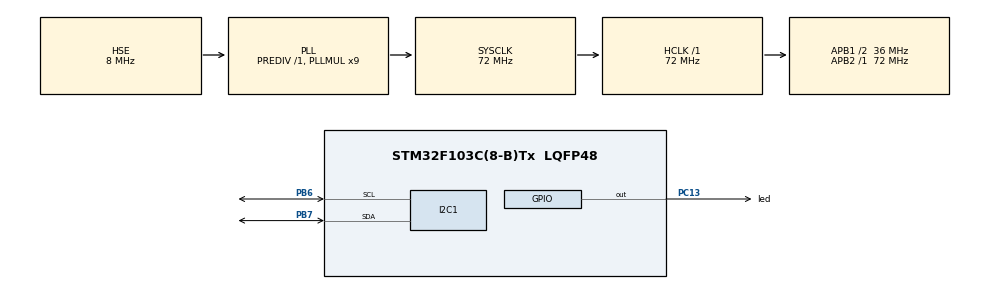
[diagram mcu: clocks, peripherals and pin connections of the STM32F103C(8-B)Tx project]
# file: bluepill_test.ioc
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I2C1.I2C_Mode=I2C_Fast
Mcu.Family=STM32F1
Mcu.Name=STM32F103C(8-B)Tx
Mcu.Package=LQFP48
NVIC.PriorityGroup=NVIC_PRIORITYGROUP_4
PA13.Mode=Serial_Wire
PA13.Signal=SYS_JTMS-SWDIO
PA14.Mode=Serial_Wire
PA14.Signal=SYS_JTCK-SWCLK
PB6.Mode=I2C
PB6.Signal=I2C1_SCL
PB7.Mode=I2C
PB7.Signal=I2C1_SDA
PC13-TAMPER-RTC.GPIO_Label=led
PC13-TAMPER-RTC.PinState=GPIO_PIN_SET
PC13-TAMPER-RTC.Signal=GPIO_Output
PD0-OSC_IN.Mode=HSE-External-Oscillator
PD0-OSC_IN.Signal=RCC_OSC_IN
PD1-OSC_OUT.Mode=HSE-External-Oscillator
PD1-OSC_OUT.Signal=RCC_OSC_OUT
ProjectManager.HeapSize=0x200
ProjectManager.StackSize=0x400
ProjectManager.TargetToolchain=SW4STM32
RCC.AHBFreq_Value=72000000
RCC.APB1CLKDivider=RCC_HCLK_DIV2
RCC.APB1Freq_Value=36000000
RCC.APB1TimFreq_Value=72000000
RCC.APB2Freq_Value=72000000
RCC.APB2TimFreq_Value=72000000
RCC.HCLKFreq_Value=72000000
RCC.PLLMUL=RCC_PLL_MUL9
RCC.PLLSourceVirtual=RCC_PLLSOURCE_HSE
RCC.SYSCLKFreq_VALUE=72000000
RCC.SYSCLKSource=RCC_SYSCLKSOURCE_PLLCLK
RCC.USBFreq_Value=72000000
board=bluepill_test

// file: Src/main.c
/**
 ******************************************************************************
 * File Name          : main.c
 * Description        : Main program body
 ******************************************************************************
 *
 * COPYRIGHT(c) 2017 STMicroelectronics
 *
 * Redistribution and use in source and binary forms, with or without modification,
 * are permitted provided that the following conditions are met:
 *   1. Redistributions of source code must retain the above copyright notice,
 *      this list of conditions and the following disclaimer.
 *   2. Redistributions in binary form must reproduce the above copyright notice,
 *      this list of conditions and the following disclaimer in the documentation
 *      and/or other materials provided with the distribution.
 *   3. Neither the name of STMicroelectronics nor the names of its contributors
 *      may be used to endorse or promote products derived from this software
 *      without specific prior written permission.
 *
 * THIS SOFTWARE IS PROVIDED BY THE COPYRIGHT HOLDERS AND CONTRIBUTORS "AS IS"
 * AND ANY EXPRESS OR IMPLIED WARRANTIES, INCLUDING, BUT NOT LIMITED TO, THE
 * IMPLIED WARRANTIES OF MERCHANTABILITY AND FITNESS FOR A PARTICULAR PURPOSE ARE
 * DISCLAIMED. IN NO EVENT SHALL THE COPYRIGHT HOLDER OR CONTRIBUTORS BE LIABLE
 * FOR ANY DIRECT, INDIRECT, INCIDENTAL, SPECIAL, EXEMPLARY, OR CONSEQUENTIAL
 * DAMAGES (INCLUDING, BUT NOT LIMITED TO, PROCUREMENT OF SUBSTITUTE GOODS OR
 * SERVICES; LOSS OF USE, DATA, OR PROFITS; OR BUSINESS INTERRUPTION) HOWEVER
 * CAUSED AND ON ANY THEORY OF LIABILITY, WHETHER IN CONTRACT, STRICT LIABILITY,
 * OR TORT (INCLUDING NEGLIGENCE OR OTHERWISE) ARISING IN ANY WAY OUT OF THE USE
 * OF THIS SOFTWARE, EVEN IF ADVISED OF THE POSSIBILITY OF SUCH DAMAGE.
 *
 ******************************************************************************
 */
#include "main.h"
#include "stm32f1xx_hal.h"

I2C_HandleTypeDef hi2c1;

/* USER CODE BEGIN PV */
/* Private variables ---------------------------------------------------------*/
#define WHO_AM_I 0x75
#define MPU_6050_ADD 0x68
#define GYRO_CONFIG 0x1B
#define ACCEL_CONFIG 0x1C
#define I2C_MST_CTRL 0x24
#define ACCEL_XOUT_H 0x3B
#define ACCEL_XOUT_L 0x3C
#define ACCEL_YOUT_H 0x3D
#define ACCEL_YOUT_L 0x3E
#define ACCEL_ZOUT_H 0x3F
#define ACCEL_ZOUT_L 0x40
#define ACCEL_8G_SENSITIVITY 4096 // LSB/g
#define TEMP_OUT_H 0x41 // temperature
#define TEMP_OUT_L 0x42
#define GYRO_XOUT_H 0x43
#define GYRO_XOUT_L 0x44
#define GYRO_YOUT_H 0x45
#define GYRO_YOUT_L 0x46
#define GYRO_ZOUT_H 0x47
#define GYRO_ZOUT_L 0x48
#define GYRO_1000_SENSITIVITY 32.8 // LSM/deg/s

uint8_t data[6], cnt;

/* USER CODE END PV */

void SystemClock_Config(void);
void Error_Handler(void);
static void MX_GPIO_Init(void);
static void MX_I2C1_Init(void);

/* USER CODE BEGIN PFP */
/* Private function prototypes -----------------------------------------------*/

/* USER CODE END PFP */

int main(void) {

	/* USER CODE BEGIN 1 */
	uint8_t settings = 0;
	/* USER CODE END 1 */

	/* MCU Configuration----------------------------------------------------------*/

	/* Reset of all peripherals, Initializes the Flash interface and the Systick. */
	HAL_Init();

	/* Configure the system clock */
	SystemClock_Config();

	/* Initialize all configured peripherals */
	MX_GPIO_Init();
	MX_I2C1_Init();

	/* USER CODE BEGIN 2 */
	settings = 0b00010000; // gyro range: 1000 deg/s
	HAL_I2C_Mem_Write(&hi2c1, MPU_6050_ADD, GYRO_CONFIG, 1, &settings, 1, 50);
	settings = 0b00010000; // accel range: 8 g
	HAL_I2C_Mem_Write(&hi2c1, MPU_6050_ADD, ACCEL_CONFIG, 1, &settings, 1, 50);
	settings = 0b00001101; // I2C 400kHz speed
	HAL_I2C_Mem_Write(&hi2c1, MPU_6050_ADD, I2C_MST_CTRL, 1, &settings, 1, 50);

	HAL_I2C_Mem_Read(&hi2c1, MPU_6050_ADD, WHO_AM_I, 1, &cnt, 1, 50);

//	HAL_I2C_Mem_Read(&hi2c1, MPU_6050_ADD, WHO_AM_I, 1, &data, 1, 50);
	if (cnt == 0x69) {
		while(1) {
			HAL_GPIO_TogglePin(led_GPIO_Port, led_Pin);
			HAL_Delay(100);
		}
	}
	/* USER CODE END 2 */

	/* Infinite loop */
	/* USER CODE BEGIN WHILE */
	while (1) {
		HAL_I2C_Mem_Read(&hi2c1, MPU_6050_ADD, ACCEL_XOUT_H, 1, &data[0], 6, 100);
		HAL_Delay(50);
		HAL_GPIO_WritePin(led_GPIO_Port, led_Pin, GPIO_PIN_SET);
		/* USER CODE END WHILE */

	}

}

/** System Clock Configuration
 */
void SystemClock_Config(void) {

	RCC_OscInitTypeDef RCC_OscInitStruct;
	RCC_ClkInitTypeDef RCC_ClkInitStruct;

	/**Initializes the CPU, AHB and APB busses clocks
	 */
	RCC_OscInitStruct.OscillatorType = RCC_OSCILLATORTYPE_HSE;
	RCC_OscInitStruct.HSEState = RCC_HSE_ON;
	RCC_OscInitStruct.HSEPredivValue = RCC_HSE_PREDIV_DIV1;
	RCC_OscInitStruct.HSIState = RCC_HSI_ON;
	RCC_OscInitStruct.PLL.PLLState = RCC_PLL_ON;
	RCC_OscInitStruct.PLL.PLLSource = RCC_PLLSOURCE_HSE;
	RCC_OscInitStruct.PLL.PLLMUL = RCC_PLL_MUL9;
	if (HAL_RCC_OscConfig(&RCC_OscInitStruct) != HAL_OK) {
		Error_Handler();
	}

	/**Initializes the CPU, AHB and APB busses clocks
	 */
	RCC_ClkInitStruct.ClockType = RCC_CLOCKTYPE_HCLK | RCC_CLOCKTYPE_SYSCLK
			| RCC_CLOCKTYPE_PCLK1 | RCC_CLOCKTYPE_PCLK2;
	RCC_ClkInitStruct.SYSCLKSource = RCC_SYSCLKSOURCE_PLLCLK;
	RCC_ClkInitStruct.AHBCLKDivider = RCC_SYSCLK_DIV1;
	RCC_ClkInitStruct.APB1CLKDivider = RCC_HCLK_DIV2;
	RCC_ClkInitStruct.APB2CLKDivider = RCC_HCLK_DIV1;

	if (HAL_RCC_ClockConfig(&RCC_ClkInitStruct, FLASH_LATENCY_2) != HAL_OK) {
		Error_Handler();
	}

	/**Configure the Systick interrupt time
	 */
	HAL_SYSTICK_Config(HAL_RCC_GetHCLKFreq() / 1000);

	/**Configure the Systick
	 */
	HAL_SYSTICK_CLKSourceConfig(SYSTICK_CLKSOURCE_HCLK);

	/* SysTick_IRQn interrupt configuration */
	HAL_NVIC_SetPriority(SysTick_IRQn, 0, 0);
}

/* I2C1 init function */
static void MX_I2C1_Init(void) {

	hi2c1.Instance = I2C1;
	hi2c1.Init.ClockSpeed = 400000;
	hi2c1.Init.DutyCycle = I2C_DUTYCYCLE_2;
	hi2c1.Init.OwnAddress1 = 0;
	hi2c1.Init.AddressingMode = I2C_ADDRESSINGMODE_7BIT;
	hi2c1.Init.DualAddressMode = I2C_DUALADDRESS_DISABLE;
	hi2c1.Init.OwnAddress2 = 0;
	hi2c1.Init.GeneralCallMode = I2C_GENERALCALL_DISABLE;
	hi2c1.Init.NoStretchMode = I2C_NOSTRETCH_DISABLE;
	if (HAL_I2C_Init(&hi2c1) != HAL_OK) {
		Error_Handler();
	}

}

/** Configure pins as
 * Analog
 * Input
 * Output
 * EVENT_OUT
 * EXTI
 */
static void MX_GPIO_Init(void) {

	GPIO_InitTypeDef GPIO_InitStruct;

	/* GPIO Ports Clock Enable */
	__HAL_RCC_GPIOC_CLK_ENABLE()
	;
	__HAL_RCC_GPIOD_CLK_ENABLE()
	;
	__HAL_RCC_GPIOA_CLK_ENABLE()
	;
	__HAL_RCC_GPIOB_CLK_ENABLE()
	;

	/*Configure GPIO pin Output Level */
	HAL_GPIO_WritePin(led_GPIO_Port, led_Pin, GPIO_PIN_SET);

	/*Configure GPIO pin : led_Pin */
	GPIO_InitStruct.Pin = led_Pin;
	GPIO_InitStruct.Mode = GPIO_MODE_OUTPUT_PP;
	GPIO_InitStruct.Speed = GPIO_SPEED_FREQ_LOW;
	HAL_GPIO_Init(led_GPIO_Port, &GPIO_InitStruct);

}

void Error_Handler(void) {
	while (1) {
	}
}

/************************ (C) COPYRIGHT STMicroelectronics *****END OF FILE****/
